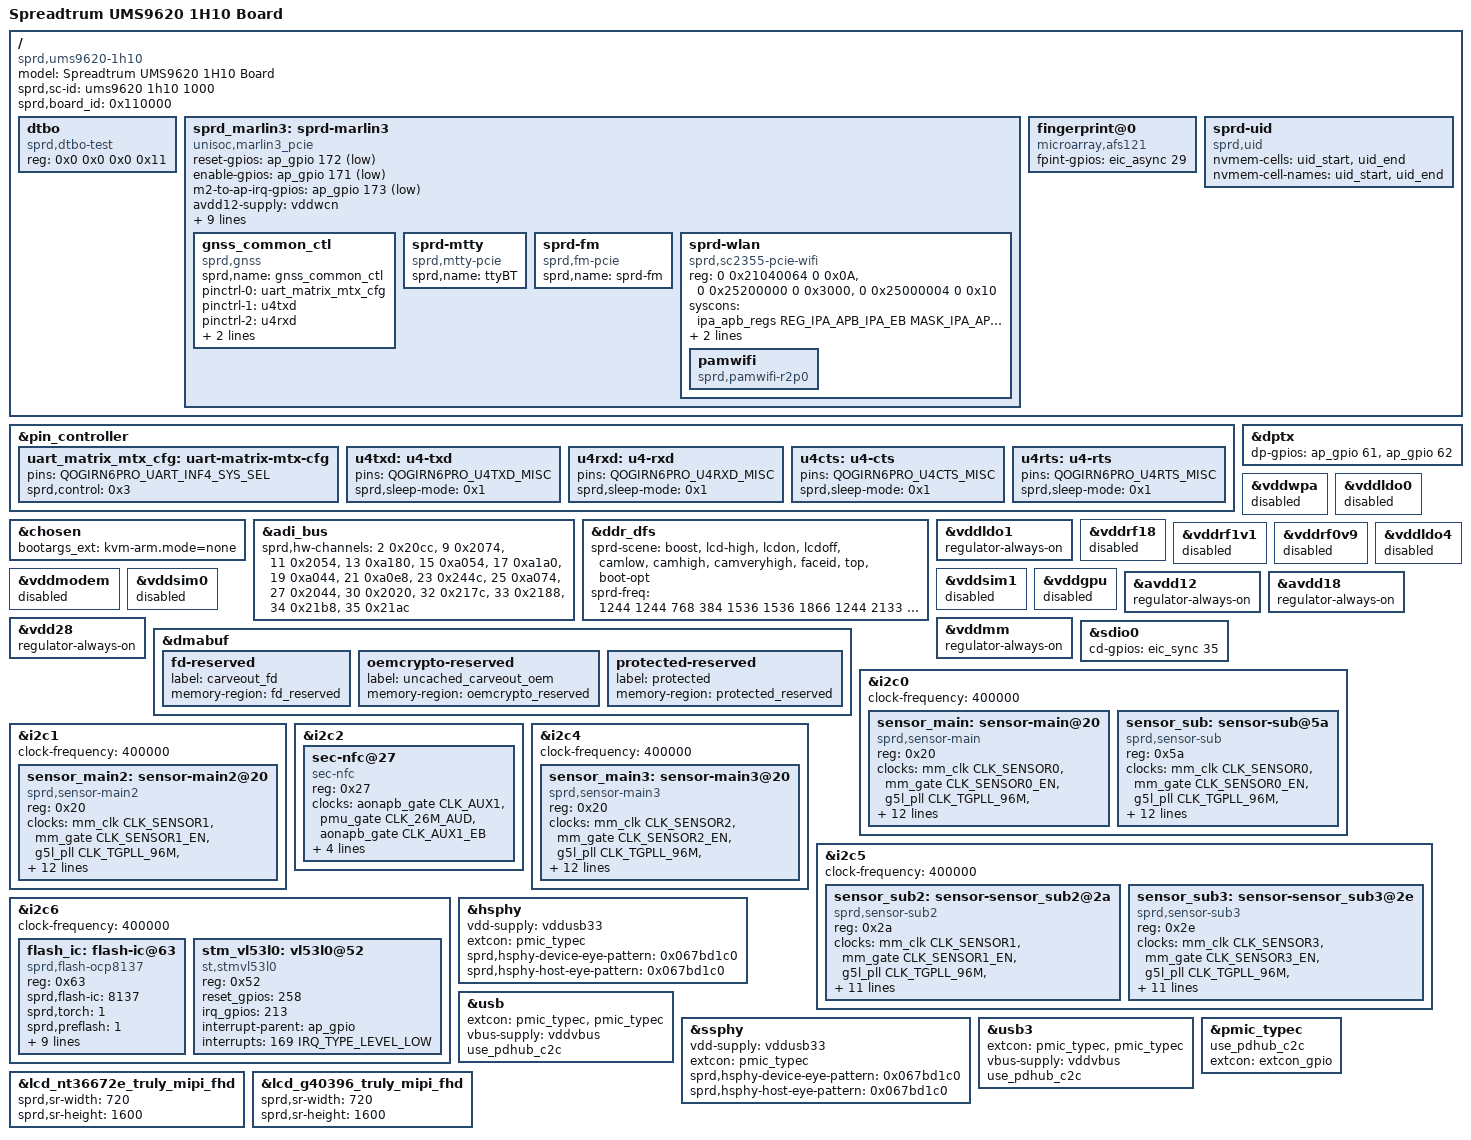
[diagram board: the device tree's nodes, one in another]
// SPDX-License-Identifier: (Licenseref-Unisoc-General-1.0 OR GPL-2.0-only)
/*
 * ums9620-1h10-overlay.dts - Unisoc platform device
 *
 * Copyright 2022 Unisoc(Shanghai) Technologies Co.Ltd
 *
 * Licensed under the Unisoc General Software License, version 1.0 (the
 * License);
 * you may not use this file except in compliance with the License.
 * You may obtain a copy of the License at
 * https://www.unisoc.com/en_us/license/UNISOC_GENERAL_LICENSE_V1.0-EN_US
 * Software distributed under the License is distributed on an "AS IS" BASIS,
 * WITHOUT WARRANTIES OF ANY KIND, either express or implied.
 * See the Unisoc General Software License, version 1.0 for more details.
 *
 * Alternatively you can use and distribute this file under the terms of the
 * GNU General Public License version 2, provided that it has to be used
 *  (including but not limited to combining, linking) with any other file under
 * the GNU General Public License version 2 on platforms that use Unisoc Chips.
 */

/dts-v1/;
/plugin/;
#include <dt-bindings/gpio/gpio.h>
#include <dt-bindings/interrupt-controller/arm-gic.h>
#include <dt-bindings/clock/sprd,ums9620-clk.h>
#include <dt-bindings/soc/sprd,qogirn6pro-regs.h>
#include <dt-bindings/soc/sprd,qogirn6pro-mask.h>
#include "lcd/amoled_g2667fp108ff_visionox_mipi_fhd.dtsi"
#include "lcd/lcd_g40396_truly_mipi_fhd.dtsi"
#include "lcd/lcd_nt36672e_truly_mipi_fhd.dtsi"
#include "lcd/lcd_td4320_truly_mipi_fhd.dtsi"
#include "lcd/lcd_dummy_mipi.dtsi"
#include "reserved-memory/ums9620-1h10-overlay.dtsi"
#include "touchscreen/ums9620-spi1-gpio13-14-tp.dtsi"
#include "battery/ums9620-1h10-overlay.dtsi"
#include "sound/ums9620-overlay.dtsi"
#include <dt-bindings/mfd/sprd,ump9620-regs.h>
#include <dt-bindings/mfd/sprd,ump9620-mask.h>
#include <dt-bindings/input/input.h>
#include <dt-bindings/clock/sprd,ums9620-clk.h>
#include "wcn/wcn_modules.h"
#include "wcn/interface/wcn-pcie-register.dtsi"
#include "wcn/chip/wcn-marlin3-sc2355-register.dtsi"

/ {

	model = "Spreadtrum UMS9620 1H10 Board";

	compatible = "sprd,ums9620-1h10", "sprd,ums9620";

	sprd,sc-id = "ums9620 1h10 1000";

	sprd,board_id = <0x110000>; //XXYY00:base board,XXYY00~XXYYFF:customize board

	fragment {
		target-path = "/";
		__overlay__ {
			#address-cells = <2>;
			#size-cells = <2>;

			dtbo: dtbo {
				compatible = "sprd,dtbo-test";
				reg = <0x0 0x0 0x0 0x11>;
			};
			sprd_marlin3: sprd-marlin3 {
				compatible = "unisoc,marlin3_pcie";
				reset-gpios = <&ap_gpio 172 GPIO_ACTIVE_LOW>;
				enable-gpios = <&ap_gpio 171 GPIO_ACTIVE_LOW>;
				m2-to-ap-irq-gpios = <&ap_gpio 173 GPIO_ACTIVE_LOW>;
				ranges;
				/* xtal-26m-clk-type = "TCXO"; */
				avdd12-supply = <&vddwcn>;
				avdd33-supply = <&vddwifipa>;
				dcxo18-supply = <&vddsim2>;
				clock-names = "clk_32k","source","enable";
				clocks = <&aonapb_gate CLK_AUX0>,
					 <&ext_32k>,
					 <&aonapb_gate CLK_AUX0_EB>;

				/* no need config dvdd12 because of share vddmem to DDR */
				/* ufs  download*/
				sprd,btwf-file-name = "/dev/block/by-name/wcnmodem";
				sprd,gnss-file-name = "/vendor/firmware/gnssmodem.bin";
				sprd,rc-ctrl = <&pcie1>;

				gnss_common_ctl {
					compatible = "sprd,gnss";
					sprd,name = "gnss_common_ctl";
					/*pinctrl*/
					pinctrl-names =
					"uart_matrix_mtx_cfg",
					"u4txd",
					"u4rxd",
					"u4cts",
					"u4rts";
					pinctrl-0 = <&uart_matrix_mtx_cfg>;
					pinctrl-1 = <&u4txd>;
					pinctrl-2 = <&u4rxd>;
					pinctrl-3 = <&u4cts>;
					pinctrl-4 = <&u4rts>;
				};

				sprd-mtty {
					compatible = "sprd,mtty-pcie";
					sprd,name = "ttyBT";
				};

				sprd-fm {
					compatible = "sprd,fm-pcie";
					sprd,name = "sprd-fm";
				};
				sprd-wlan {
					compatible = "sprd,sc2355-pcie-wifi";
					reg = <0 0x21040064 0 0x0A>,
						<0 0x25200000 0 0x3000>,
						<0 0x25000004 0 0x10>;
					reg-names = "wifi_ipaqos",
						"pam_wifi_reg_base_remap",
						"pamwifi_subsys_base";
					syscons = <&ipa_apb_regs
							REG_IPA_APB_IPA_EB
							MASK_IPA_APB_PAM_WIFI_EB>;
					syscon-names = "enable";
					interrupts = <GIC_SPI 139 IRQ_TYPE_LEVEL_HIGH>;
					interrupt-names = "pam-wifi-irq";
					pamwifi {
						compatible = "sprd,pamwifi-r2p0";
					};
				};
			};

			fingerprint@0 {
				compatible = "microarray,afs121";
				fpint-gpios = <&eic_async 29 0>;
			};

			sprd-uid {
				compatible = "sprd,uid";
				nvmem-cells = <&uid_start>, <&uid_end>;
				nvmem-cell-names = "uid_start", "uid_end";
			};

		};
	};
};

&pin_controller {
	uart_matrix_mtx_cfg: uart-matrix-mtx-cfg {
		pins = "QOGIRN6PRO_UART_INF4_SYS_SEL";
		sprd,control = <0x3>;
	};

	u4txd: u4-txd {
		pins = "QOGIRN6PRO_U4TXD_MISC";
		sprd,sleep-mode = <0x1>;
	};

	u4rxd: u4-rxd {
		pins = "QOGIRN6PRO_U4RXD_MISC";
		sprd,sleep-mode = <0x1>;
	};

	u4cts: u4-cts {
		pins = "QOGIRN6PRO_U4CTS_MISC";
		sprd,sleep-mode = <0x1>;
	};

	u4rts: u4-rts {
		pins = "QOGIRN6PRO_U4RTS_MISC";
		sprd,sleep-mode = <0x1>;
	};
};

&chosen {
	bootargs_ext = "kvm-arm.mode=none";
};

&adi_bus {
	sprd,hw-channels = <2 0x20cc>, <9 0x2074>, <11 0x2054>, <13 0xa180>,
			<15 0xa054>, <17 0xa1a0>, <19 0xa044>, <21 0xa0e8>,
			<23 0x244c>, <25 0xa074>, <27 0x2044>, <30 0x2020>,
			<32 0x217c>, <33 0x2188>, <34 0x21b8>, <35 0x21ac>;
};

&ddr_dfs {
		sprd-scene = "boost", "lcd-high", "lcdon", "lcdoff", "camlow",
			"camhigh", "camveryhigh", "faceid", "top", "boot-opt";
		sprd-freq = <1244 1244 768 384 1536 1536 1866 1244 2133 2133>;
};

&dptx {
	dp-gpios = <&ap_gpio 61 GPIO_ACTIVE_HIGH>,
			<&ap_gpio 62 GPIO_ACTIVE_HIGH>;
};

&vddwpa {
	status = "disabled";
};

&vddldo0 {
	status = "disabled";
};

&vddldo1 {
	regulator-always-on;
};

&vddrf18 {
	status = "disabled";
};

&vddrf1v1 {
	status = "disabled";
};

&vddrf0v9 {
	status = "disabled";
};

&vddldo4 {
	status = "disabled";
};

&vddmodem {
	status = "disabled";
};

&vddsim0 {
	status = "disabled";
};

&vddsim1 {
	status = "disabled";
};

&vddgpu {
	status = "disabled";
};

&avdd12 {
	regulator-always-on;
};

&avdd18 {
	regulator-always-on;
};

&vdd28 {
	regulator-always-on;
};

&vddmm {
	regulator-always-on;
};

&dmabuf {

	fd-reserved {
		label = "carveout_fd";
		memory-region = <&fd_reserved>;
	};

	oemcrypto-reserved {
		label = "uncached_carveout_oem";
		memory-region = <&oemcrypto_reserved>;
	};

	protected-reserved {
		label = "protected";
		memory-region = <&protected_reserved>;
	};
};

&sdio0 {
	cd-gpios = <&eic_sync 35 GPIO_ACTIVE_HIGH>;
};

&i2c0 {
	status = "okay";
	clock-frequency = <400000>;

	sensor_main: sensor-main@20 {
		compatible = "sprd,sensor-main";
		reg = <0x20>;
		clock-names = "clk_src","sensor_eb",
			"clk_96m","clk_64m",
			"clk_51m2","clk_48m","clk_26m";
		clocks = <&mm_clk CLK_SENSOR0>,<&mm_gate CLK_SENSOR0_EN>,
				<&g5l_pll CLK_TGPLL_96M>,<&g5l_pll CLK_TGPLL_64M>,
				<&g5l_pll CLK_TGPLL_51M2>,<&g5l_pll CLK_TGPLL_48M>,<&ext_26m>;
		vddio-supply = <&vddcamio>;
		vddcama-supply = <&vddcama0>;
		vddcamd-supply = <&vddcamd0>;
		vddcammot-supply = <&vddcammot0>;
		reset-gpios = <&ap_gpio 40 0>;
		power-down-gpios = <&ap_gpio 46 0>;
		sprd,phyid = <0>;
		csi = <&csi0>;
		power-domains = <&mm_domain>;
	};

	sensor_sub: sensor-sub@5a {
		compatible = "sprd,sensor-sub";
		reg = <0x5a>;
		clock-names = "clk_src","sensor_eb",
			"clk_96m","clk_64m",
			"clk_51m2","clk_48m","clk_26m";
		clocks = <&mm_clk CLK_SENSOR0>,<&mm_gate CLK_SENSOR0_EN>,
			<&g5l_pll CLK_TGPLL_96M>,<&g5l_pll CLK_TGPLL_64M>,
			<&g5l_pll CLK_TGPLL_51M2>,<&g5l_pll CLK_TGPLL_48M>,<&ext_26m>;
		vddio-supply = <&vddcamio>;
		vddcama-supply = <&vddcama0>;
		vddcamd-supply = <&vddcamd0>;
		vddcammot-supply = <&vddcammot0>;
		reset-gpios = <&ap_gpio 39 0>;
		power-down-gpios = <&ap_gpio 45 0>;
		sprd,phyid = <1>;
		csi = <&csi1>;
		power-domains = <&mm_domain>;
	};
};

&i2c1 {
	status = "okay";
	clock-frequency = <400000>;

	sensor_main2: sensor-main2@20 {
		compatible = "sprd,sensor-main2";
		reg = <0x20>;
		clock-names = "clk_src","sensor_eb",
			"clk_96m","clk_64m",
			"clk_51m2","clk_48m","clk_26m";
		clocks = <&mm_clk CLK_SENSOR1>,<&mm_gate CLK_SENSOR1_EN>,
			<&g5l_pll CLK_TGPLL_96M>,<&g5l_pll CLK_TGPLL_64M>,
			<&g5l_pll CLK_TGPLL_51M2>,<&g5l_pll CLK_TGPLL_48M>,<&ext_26m>;
		vddio-supply = <&vddcamio>;
		vddcama-supply = <&vddcama1>;
		vddcamd-supply = <&vddcamd1>;
		reset-gpios = <&ap_gpio 41 0>;
		avdd-gpios = <&ap_gpio 79 0>;
		power-down-gpios = <&ap_gpio 47 0>;
		sprd,phyid = <3>;/*6*/
		csi = <&csi3>;
		power-domains = <&mm_domain>;
	};
};

&i2c2 {
	status = "okay";
	#address-cells = <1>;
	#size-cells = <0>;

	sec-nfc@27 {
		compatible = "sec-nfc";
		reg = <0x27>;
		clock-names = "nfc_clk","source","enable";
		clocks = <&aonapb_gate CLK_AUX1>, <&pmu_gate CLK_26M_AUD>, <&aonapb_gate CLK_AUX1_EB>;
		sec-nfc,ven-gpio = <&ap_gpio 150 0>;
		sec-nfc,firm-gpio = <&ap_gpio 111 0>;
		sec-nfc,irq-gpio = <&ap_gpio 112 0>;
		sec-nfc,clk-req = <&ap_gpio 147 0>;
	};
};

&i2c4 {
	status = "okay";
	clock-frequency = <400000>;

	sensor_main3: sensor-main3@20 {
		compatible = "sprd,sensor-main3";
		reg = <0x20>;
		clock-names = "clk_src","sensor_eb",
			"clk_96m","clk_64m",
			"clk_51m2","clk_48m","clk_26m";
		clocks = <&mm_clk CLK_SENSOR2>,<&mm_gate CLK_SENSOR2_EN>,
			<&g5l_pll CLK_TGPLL_96M>,<&g5l_pll CLK_TGPLL_64M>,
			<&g5l_pll CLK_TGPLL_51M2>,<&g5l_pll CLK_TGPLL_48M>,<&ext_26m>;
		vddio-supply = <&vddcamio>;
		vddcama-supply = <&vddcama2>;
		vddcamd-supply = <&vddcamd2>;
		vddcammot-supply = <&vddcammot1>;
		mot-gpios = <&ap_gpio 78 0>;
		reset-gpios = <&ap_gpio 42 0>;
		sprd,phyid = <2>;/*4*/
		csi = <&csi2>;
		power-domains = <&mm_domain>;
	};
};

&i2c5 {
	status = "okay";
	clock-frequency = <400000>;

	sensor_sub2: sensor-sensor_sub2@2a {
		compatible = "sprd,sensor-sub2";
		reg = <0x2a>;
		clock-names = "clk_src","sensor_eb",
			"clk_96m","clk_64m",
			"clk_51m2","clk_48m","clk_26m";
		clocks = <&mm_clk CLK_SENSOR1>,<&mm_gate CLK_SENSOR1_EN>,
			<&g5l_pll CLK_TGPLL_96M>,<&g5l_pll CLK_TGPLL_64M>,
			<&g5l_pll CLK_TGPLL_51M2>,<&g5l_pll CLK_TGPLL_48M>,<&ext_26m>;
		vddio-supply = <&vddcamio>;
		vddcama-supply = <&vddcama1>;
		vddcamd-supply = <&vddcamd1>;
		reset-gpios = <&ap_gpio 44 0>;
		power-down-gpios = <&ap_gpio 50 0>;
		sprd,phyid = <5>;
		csi = <&csi2>;
		power-domains = <&mm_domain>;
	};

	sensor_sub3: sensor-sensor_sub3@2e {
		compatible = "sprd,sensor-sub3";
		reg = <0x2e>;
		clock-names = "clk_src","sensor_eb",
			"clk_96m","clk_64m",
			"clk_51m2","clk_48m","clk_26m";
		clocks = <&mm_clk CLK_SENSOR3>,<&mm_gate CLK_SENSOR3_EN>,
			<&g5l_pll CLK_TGPLL_96M>,<&g5l_pll CLK_TGPLL_64M>,
			<&g5l_pll CLK_TGPLL_51M2>,<&g5l_pll CLK_TGPLL_48M>,<&ext_26m>;
		vddio-supply = <&vddcamio>;
		vddcama-supply = <&vddcama2>;
		vddcamd-supply = <&vddcamd2>;
		reset-gpios = <&ap_gpio 43 0>;
		power-down-gpios = <&ap_gpio 49 0>;
		sprd,phyid = <7>;
		csi = <&csi3>;
		power-domains = <&mm_domain>;
	};
};

&i2c6 {
	status = "okay";
	clock-frequency = <400000>;

	flash_ic: flash-ic@63 {
		compatible = "sprd,flash-ocp8137";
		reg = <0x63>;
		sprd,flash-ic = <8137>;
		sprd,torch = <1>;
		sprd,preflash = <1>;
		sprd,highlight = <1>;
		sprd,torch-level = <128>;
		sprd,preflash-level = <128>;
		sprd,highlight-level = <128>;
		sprd,lvfm-enable = <1>;
		flash-torch-en-gpios = <&ap_gpio 153 0>;
		flash-chip-en-gpios = <&ap_gpio 119 0>;
		flash-en-gpios = <&ap_gpio 152 0>;
		flash-sync-gpios = <&ap_gpio 151 0>;
	};

	stm_vl53l0: vl53l0@52 {
		compatible = "st,stmvl53l0";
		reg = <0x52>;
		reset_gpios = <258>;
		irq_gpios = <213>;
		interrupt-parent = <&ap_gpio>;
		interrupts = <169 IRQ_TYPE_LEVEL_LOW>;
	};
};

&hsphy {
	vdd-supply = <&vddusb33>;
	extcon = <&pmic_typec>;
	sprd,hsphy-device-eye-pattern = <0x067bd1c0>;
	sprd,hsphy-host-eye-pattern = <0x067bd1c0>;
	status = "okay";
};

&usb {
	extcon = <&pmic_typec>, <&pmic_typec>;
	vbus-supply = <&vddvbus>;
	use_pdhub_c2c;
	status = "okay";
};

&ssphy {
	vdd-supply = <&vddusb33>;
	extcon = <&pmic_typec>;
	sprd,hsphy-device-eye-pattern = <0x067bd1c0>;
	sprd,hsphy-host-eye-pattern = <0x067bd1c0>;
	status = "okay";
};

&usb3 {
	extcon = <&pmic_typec>, <&pmic_typec>;
	vbus-supply = <&vddvbus>;
	use_pdhub_c2c;
	status = "okay";
};

&pmic_typec {
	use_pdhub_c2c;
	extcon = <&extcon_gpio>;
	status = "okay";
};

&lcd_nt36672e_truly_mipi_fhd {
	sprd,sr-width = <720>;
	sprd,sr-height = <1600>;
};

&lcd_g40396_truly_mipi_fhd {
	sprd,sr-width = <720>;
	sprd,sr-height = <1600>;
};
